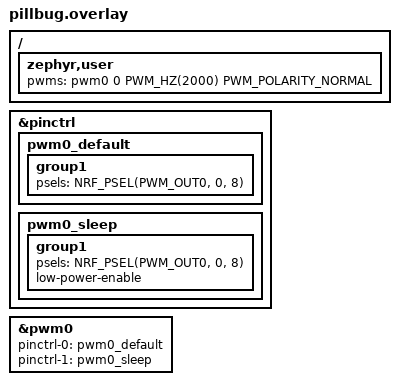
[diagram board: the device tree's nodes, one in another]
/*
 * Copyright (c) 2026 The ZMK Contributors
 *
 * SPDX-License-Identifier: MIT
 */

/*
 * Piezo buzzer (BZ1 on the Pillzmod PCB) is wired to PA10 in the
 * Blackpill-compatible connector numbering (pin 31), which maps to
 * P0.08 / gpio0 pin 8 on the PillBug's nRF52840. Drive it from PWM0.
 */

#include <zephyr/dt-bindings/pinctrl/nrf-pinctrl.h>
#include <zephyr/dt-bindings/pwm/pwm.h>

&pinctrl {
    pwm0_default: pwm0_default {
        group1 {
            psels = <NRF_PSEL(PWM_OUT0, 0, 8)>;
        };
    };

    pwm0_sleep: pwm0_sleep {
        group1 {
            psels = <NRF_PSEL(PWM_OUT0, 0, 8)>;
            low-power-enable;
        };
    };
};

&pwm0 {
    status = "okay";
    pinctrl-0 = <&pwm0_default>;
    pinctrl-1 = <&pwm0_sleep>;
    pinctrl-names = "default", "sleep";
};

/ {
    zephyr,user {
        pwms = <&pwm0 0 PWM_HZ(2000) PWM_POLARITY_NORMAL>;
    };
};
